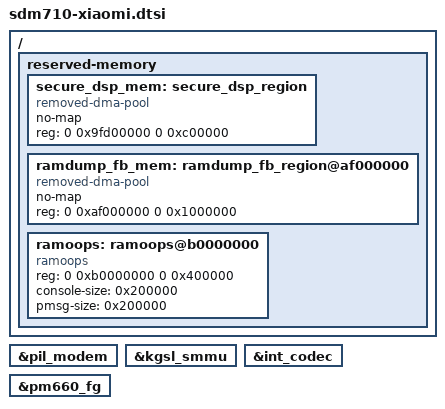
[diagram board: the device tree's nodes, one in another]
/* SPDX-License-Identifier: GPL-2.0-only */

/ {
	reserved-memory {
		secure_dsp_mem: secure_dsp_region {
			compatible = "removed-dma-pool";
			no-map;
			reg = <0 0x9fd00000 0 0xc00000>;
		};

		ramdump_fb_mem: ramdump_fb_region@af000000 {
			compatible = "removed-dma-pool";
			no-map;
			reg = <0 0xaf000000 0 0x1000000>;
		};

		ramoops: ramoops@b0000000 {
			compatible = "ramoops";
			reg = <0 0xb0000000 0 0x400000>;
			console-size = <0x200000>;
			pmsg-size = <0x200000>;
		};
	};
};

/* sdm670.dtsi */
&pil_modem {
	/delete-property/ qcom,minidump-id;
};

/* msm-arm-smmu-sdm670.dtsi */
&kgsl_smmu {
	/delete-property/ qcom,deferred-regulator-disable-delay;
};

/* sdm670-audio.dtsi */
&int_codec {
	/delete-property/ qcom,ext-disp-audio-rx;
};

/* sdm670-pmic-overlay.dtsi */
#include "sdm670-pmic-overlay.dtsi"

&pm660_fg {
	/delete-property/ qcom,hold-soc-while-full;
};
